# iostr752 register map
Registers are 16-bit, access not given, no defined reset value unless marked. A register's access mark holds for its fields unless they carry their own. Addresses are absolute; registers are grouped by the start of their names; [hi:lo] are bit positions; {n}, {i} and the like mark numbered series.

## SMI
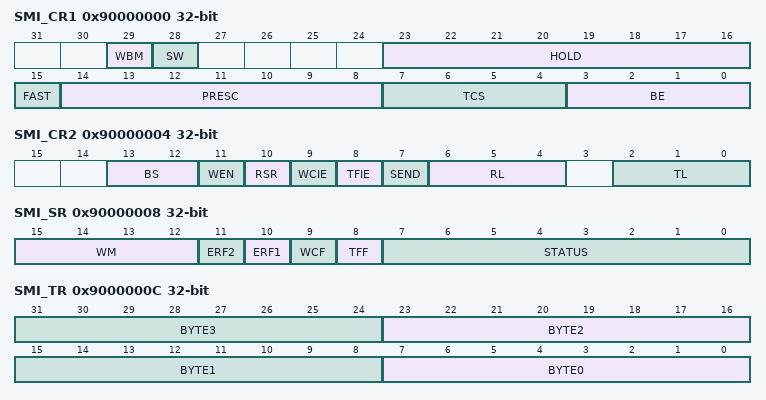
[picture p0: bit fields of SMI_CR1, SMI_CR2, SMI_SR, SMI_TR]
0x90000000 SMI_CR1 32-bit
  [29] WBM, [28] SW, [23:16] HOLD, [15] FAST, [14:8] PRESC, [7:4] TCS, [3:0] BE
0x90000004 SMI_CR2 32-bit
  [13:12] BS, [11] WEN, [10] RSR, [9] WCIE, [8] TFIE, [7] SEND, [6:4] RL, [2:0] TL
0x90000008 SMI_SR 32-bit
  [15:12] WM, [11] ERF2, [10] ERF1, [9] WCF, [8] TFF, [7:0] STATUS
0x9000000C SMI_TR 32-bit
  [8n+7:8n] BYTE{n} (n=0..3)
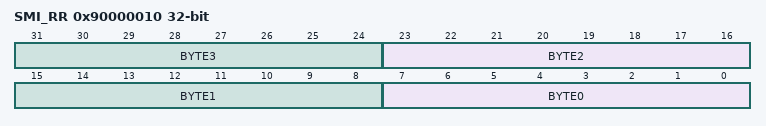
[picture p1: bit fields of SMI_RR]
0x90000010 SMI_RR 32-bit
  [8n+7:8n] BYTE{n} (n=0..3)

## RTC
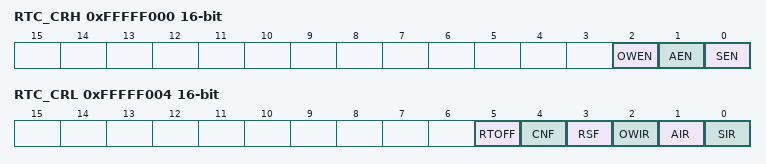
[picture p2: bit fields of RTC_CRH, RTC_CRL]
0xFFFFF000 RTC_CRH
  [2] OWEN, [1] AEN, [0] SEN
0xFFFFF004 RTC_CRL
  [5] RTOFF, [4] CNF, [3] RSF, [2] OWIR, [1] AIR, [0] SIR
0xFFFFF008 RTC_PRLH
  [3:0] PRL
0xFFFFF00C RTC_PRLL
0xFFFFF010 RTC_DIVH
  [3:0] RTC_DIV
0xFFFFF014 RTC_DIVL
0xFFFFF018 RTC_CNTH
0xFFFFF01C RTC_CNTL
0xFFFFF020 RTC_ALRH
0xFFFFF024 RTC_ALRL

## WDG
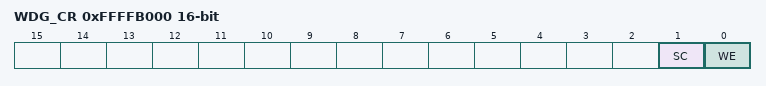
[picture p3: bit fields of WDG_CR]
0xFFFFB000 WDG_CR
  [1] SC, [0] WE
0xFFFFB004 WDG_PR
  [7:0] PR
0xFFFFB008 WDG_VR
0xFFFFB00C WDG_CNT
0xFFFFB010 WDG_SR
  [0] EC
0xFFFFB014 WDG_MR
  [0] ECM
0xFFFFB018 WDG_KR

## TB
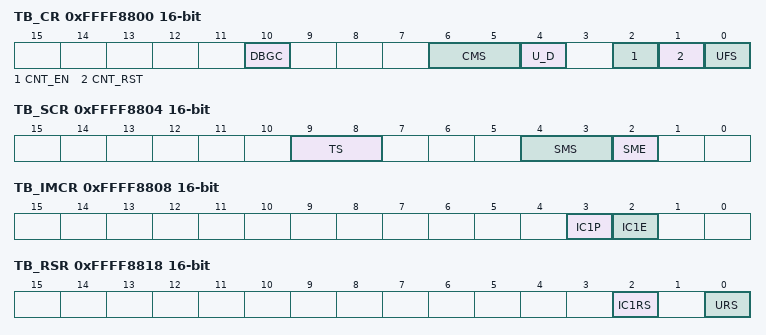
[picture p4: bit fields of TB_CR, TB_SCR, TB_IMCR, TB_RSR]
0xFFFF8800 TB_CR
  [10] DBGC, [6:5] CMS, [4] U_D, [2] CNT_EN, [1] CNT_RST, [0] UFS
0xFFFF8804 TB_SCR
  [9:8] TS, [4:3] SMS, [2] SME
0xFFFF8808 TB_IMCR
  [3] IC1P, [2] IC1E
0xFFFF8818 TB_RSR
  [2] IC1RS, [0] URS
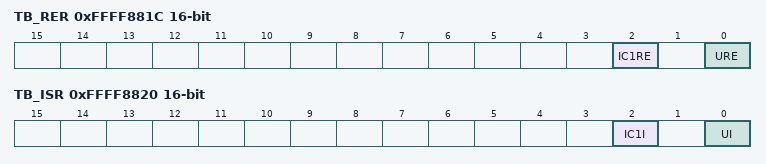
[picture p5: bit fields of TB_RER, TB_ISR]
0xFFFF881C TB_RER
  [2] IC1RE, [0] URE
0xFFFF8820 TB_ISR
  [2] IC1I, [0] UI
0xFFFF8824 TB_CNT
0xFFFF8828 TB_PSC
0xFFFF8830 TB_ARR
0xFFFF884C TB_ICR1

## TIM0
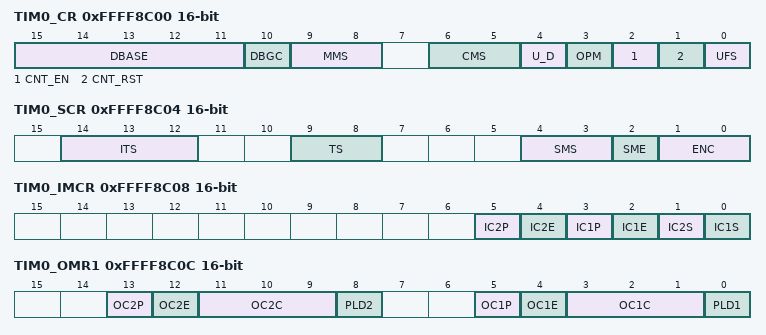
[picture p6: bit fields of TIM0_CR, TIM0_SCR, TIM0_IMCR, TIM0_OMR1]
0xFFFF8C00 TIM0_CR
  [15:11] DBASE, [10] DBGC, [9:8] MMS, [6:5] CMS, [4] U_D, [3] OPM, [2] CNT_EN, [1] CNT_RST, [0] UFS
0xFFFF8C04 TIM0_SCR
  [14:12] ITS, [9:8] TS, [4:3] SMS, [2] SME, [1:0] ENC
0xFFFF8C08 TIM0_IMCR
  [5] IC2P, [4] IC2E, [3] IC1P, [2] IC1E, [1] IC2S, [0] IC1S
0xFFFF8C0C TIM0_OMR1
  [13] OC2P, [12] OC2E, [11:9] OC2C, [8] PLD2, [5] OC1P, [4] OC1E, [3:1] OC1C, [0] PLD1
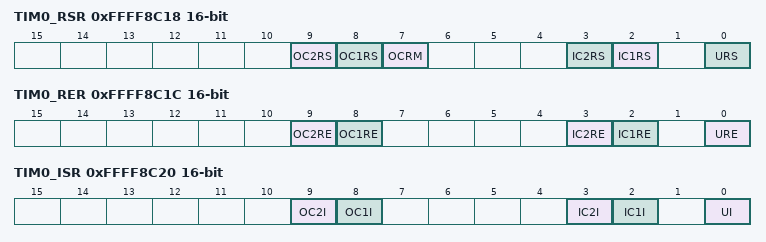
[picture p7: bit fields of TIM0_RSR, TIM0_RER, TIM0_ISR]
0xFFFF8C18 TIM0_RSR
  [9] OC2RS, [8] OC1RS, [7] OCRM, [3] IC2RS, [2] IC1RS, [0] URS
0xFFFF8C1C TIM0_RER
  [9] OC2RE, [8] OC1RE, [3] IC2RE, [2] IC1RE, [0] URE
0xFFFF8C20 TIM0_ISR
  [9] OC2I, [8] OC1I, [3] IC2I, [2] IC1I, [0] UI
0xFFFF8C24 TIM0_CNT
0xFFFF8C28 TIM0_PSC
0xFFFF8C30 TIM0_ARR
0xFFFF8C34 TIM0_OCR1
0xFFFF8C38 TIM0_OCR2
0xFFFF8C4C TIM0_ICR1
0xFFFF8C50 TIM0_ICR2
0xFFFF8C60 TIM0_DMAB

## TIM1
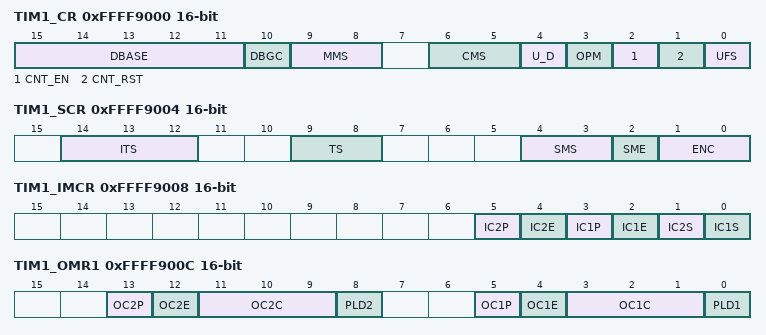
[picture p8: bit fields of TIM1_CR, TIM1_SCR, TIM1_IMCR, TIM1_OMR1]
0xFFFF9000 TIM1_CR
  [15:11] DBASE, [10] DBGC, [9:8] MMS, [6:5] CMS, [4] U_D, [3] OPM, [2] CNT_EN, [1] CNT_RST, [0] UFS
0xFFFF9004 TIM1_SCR
  [14:12] ITS, [9:8] TS, [4:3] SMS, [2] SME, [1:0] ENC
0xFFFF9008 TIM1_IMCR
  [5] IC2P, [4] IC2E, [3] IC1P, [2] IC1E, [1] IC2S, [0] IC1S
0xFFFF900C TIM1_OMR1
  [13] OC2P, [12] OC2E, [11:9] OC2C, [8] PLD2, [5] OC1P, [4] OC1E, [3:1] OC1C, [0] PLD1
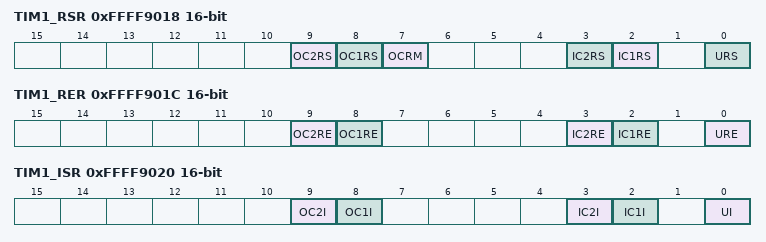
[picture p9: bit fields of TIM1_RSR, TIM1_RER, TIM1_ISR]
0xFFFF9018 TIM1_RSR
  [9] OC2RS, [8] OC1RS, [7] OCRM, [3] IC2RS, [2] IC1RS, [0] URS
0xFFFF901C TIM1_RER
  [9] OC2RE, [8] OC1RE, [3] IC2RE, [2] IC1RE, [0] URE
0xFFFF9020 TIM1_ISR
  [9] OC2I, [8] OC1I, [3] IC2I, [2] IC1I, [0] UI
0xFFFF9024 TIM1_CNT
0xFFFF9028 TIM1_PSC
0xFFFF9030 TIM1_ARR
0xFFFF9034 TIM1_OCR1
0xFFFF9038 TIM1_OCR2
0xFFFF904C TIM1_ICR1
0xFFFF9050 TIM1_ICR2
0xFFFF9060 TIM1_DMAB

## TIM2
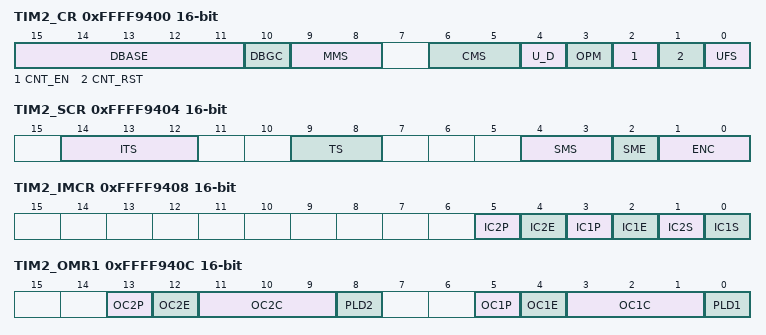
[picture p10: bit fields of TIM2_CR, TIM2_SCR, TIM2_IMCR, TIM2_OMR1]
0xFFFF9400 TIM2_CR
  [15:11] DBASE, [10] DBGC, [9:8] MMS, [6:5] CMS, [4] U_D, [3] OPM, [2] CNT_EN, [1] CNT_RST, [0] UFS
0xFFFF9404 TIM2_SCR
  [14:12] ITS, [9:8] TS, [4:3] SMS, [2] SME, [1:0] ENC
0xFFFF9408 TIM2_IMCR
  [5] IC2P, [4] IC2E, [3] IC1P, [2] IC1E, [1] IC2S, [0] IC1S
0xFFFF940C TIM2_OMR1
  [13] OC2P, [12] OC2E, [11:9] OC2C, [8] PLD2, [5] OC1P, [4] OC1E, [3:1] OC1C, [0] PLD1
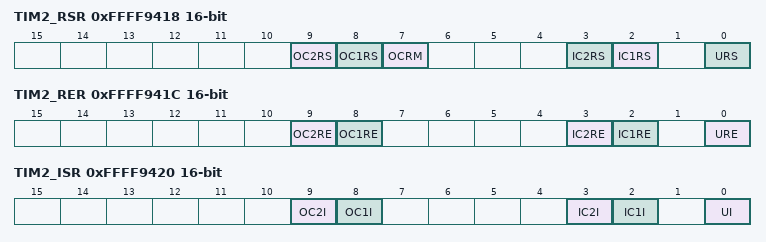
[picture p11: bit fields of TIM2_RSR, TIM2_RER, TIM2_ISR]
0xFFFF9418 TIM2_RSR
  [9] OC2RS, [8] OC1RS, [7] OCRM, [3] IC2RS, [2] IC1RS, [0] URS
0xFFFF941C TIM2_RER
  [9] OC2RE, [8] OC1RE, [3] IC2RE, [2] IC1RE, [0] URE
0xFFFF9420 TIM2_ISR
  [9] OC2I, [8] OC1I, [3] IC2I, [2] IC1I, [0] UI
0xFFFF9424 TIM2_CNT
0xFFFF9428 TIM2_PSC
0xFFFF9430 TIM2_ARR
0xFFFF9434 TIM2_OCR1
0xFFFF9438 TIM2_OCR2
0xFFFF944C TIM2_ICR1
0xFFFF9450 TIM2_ICR2
0xFFFF9460 TIM2_DMAB
